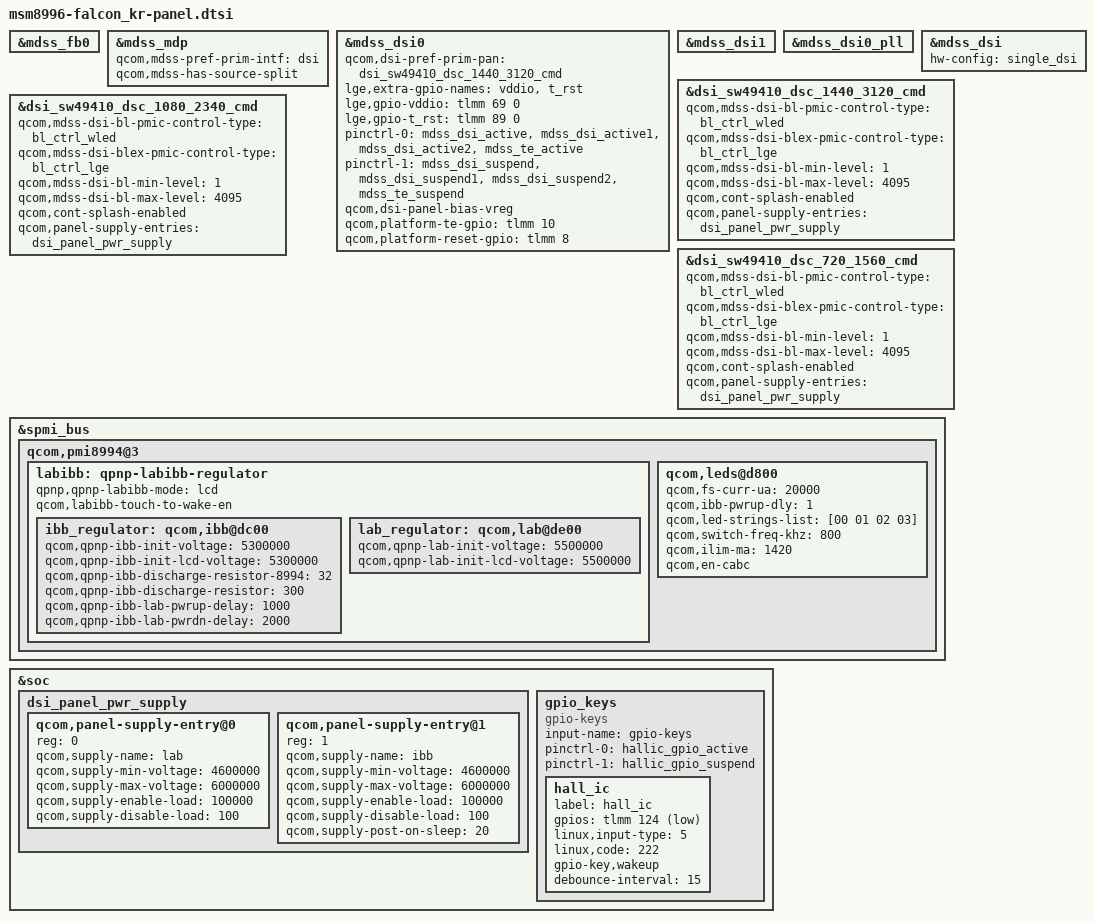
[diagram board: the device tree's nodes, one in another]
/* Copyright (c) 2015, The Linux Foundation. All rights reserved.
 *
 * This program is free software; you can redistribute it and/or modify
 * it under the terms of the GNU General Public License version 2 and
 * only version 2 as published by the Free Software Foundation.
 *
 * This program is distributed in the hope that it will be useful,
 * but WITHOUT ANY WARRANTY; without even the implied warranty of
 * MERCHANTABILITY or FITNESS FOR A PARTICULAR PURPOSE.  See the
 * GNU General Public License for more details.
 */

#include "../dsi-panel-sw49410-dsc-1440-3120-cmd.dtsi"
#include "../dsi-panel-sw49410-dsc-1080-2340-cmd.dtsi"
#include "../dsi-panel-sw49410-dsc-720-1560-cmd.dtsi"

&mdss_fb0 {
	/delete-node/ qcom,cont-splash-memory;
};

&mdss_mdp {
	qcom,mdss-pref-prim-intf = "dsi";
	qcom,mdss-has-source-split;
};

&mdss_dsi0 {
	qcom,dsi-pref-prim-pan = <&dsi_sw49410_dsc_1440_3120_cmd>;
	lge,extra-gpio-names = "vddio", "t_rst";
	lge,gpio-vddio = <&tlmm 69 0>;
	lge,gpio-t_rst = <&tlmm 89 0>;
	pinctrl-names = "mdss_default", "mdss_sleep";
	pinctrl-0 = <&mdss_dsi_active &mdss_dsi_active1 &mdss_dsi_active2  &mdss_te_active>;
	pinctrl-1 = <&mdss_dsi_suspend &mdss_dsi_suspend1 &mdss_dsi_suspend2 &mdss_te_suspend>;
	qcom,dsi-panel-bias-vreg;
	qcom,platform-te-gpio = <&tlmm 10 0>;
	qcom,platform-reset-gpio = <&tlmm 8 0>;

	/delete-property/vddio-supply;
	/delete-property/qcom,null-insertion-enabled;
};

&mdss_dsi1 {
	/delete-property/cell-index;
};

&mdss_dsi0_pll {
		/delete-property/ memory-region;
};

&mdss_dsi {
	hw-config = "single_dsi";
};

&labibb {
	status = "ok";
	qpnp,qpnp-labibb-mode = "lcd";
	qcom,labibb-touch-to-wake-en;
};

&ibb_regulator {
	qcom,qpnp-ibb-discharge-resistor-8994 = <32>;
	qcom,qpnp-ibb-discharge-resistor = <300>;
	qcom,qpnp-ibb-lab-pwrup-delay = <1000>;
	qcom,qpnp-ibb-lab-pwrdn-delay = <2000>;
};

&dsi_sw49410_dsc_1440_3120_cmd {
	qcom,mdss-dsi-bl-pmic-control-type = "bl_ctrl_wled";
	qcom,mdss-dsi-blex-pmic-control-type = "bl_ctrl_lge";
	qcom,mdss-dsi-bl-min-level = <1>;
	qcom,mdss-dsi-bl-max-level = <4095>;
	qcom,cont-splash-enabled;
	qcom,panel-supply-entries = <&dsi_panel_pwr_supply>;
};

&dsi_sw49410_dsc_1080_2340_cmd {
	qcom,mdss-dsi-bl-pmic-control-type = "bl_ctrl_wled";
	qcom,mdss-dsi-blex-pmic-control-type = "bl_ctrl_lge";
	qcom,mdss-dsi-bl-min-level = <1>;
	qcom,mdss-dsi-bl-max-level = <4095>;
	qcom,cont-splash-enabled;
	qcom,panel-supply-entries = <&dsi_panel_pwr_supply>;
};

&dsi_sw49410_dsc_720_1560_cmd {
	qcom,mdss-dsi-bl-pmic-control-type = "bl_ctrl_wled";
	qcom,mdss-dsi-blex-pmic-control-type = "bl_ctrl_lge";
	qcom,mdss-dsi-bl-min-level = <1>;
	qcom,mdss-dsi-bl-max-level = <4095>;
	qcom,cont-splash-enabled;
	qcom,panel-supply-entries = <&dsi_panel_pwr_supply>;
};

&spmi_bus {
	qcom,pmi8994@3 {
		labibb: qpnp-labibb-regulator {
			ibb_regulator: qcom,ibb@dc00 {
				qcom,qpnp-ibb-init-voltage = <5300000>;
				qcom,qpnp-ibb-init-lcd-voltage = <5300000>;
			};
			lab_regulator: qcom,lab@de00 {
				qcom,qpnp-lab-init-voltage = <5500000>;
				qcom,qpnp-lab-init-lcd-voltage = <5500000>;
			};
		};

		qcom,leds@d800 {
			qcom,fs-curr-ua = <20000>;
			qcom,ibb-pwrup-dly = <1>;
			qcom,led-strings-list = [00 01 02 03];
			qcom,switch-freq-khz = <800>;
			qcom,ilim-ma = <1420>;
			qcom,en-cabc;
		};
	};
};

&soc {
	dsi_panel_pwr_supply: dsi_panel_pwr_supply {
		#address-cells = <1>;
		#size-cells = <0>;

		qcom,panel-supply-entry@0 {
			reg = <0>;
			qcom,supply-name = "lab";
			qcom,supply-min-voltage = <4600000>;
			qcom,supply-max-voltage = <6000000>;
			qcom,supply-enable-load = <100000>;
			qcom,supply-disable-load = <100>;
		};

		qcom,panel-supply-entry@1 {
			reg = <1>;
			qcom,supply-name = "ibb";
			qcom,supply-min-voltage = <4600000>;
			qcom,supply-max-voltage = <6000000>;
			qcom,supply-enable-load = <100000>;
			qcom,supply-disable-load = <100>;
			qcom,supply-post-on-sleep = <20>;
		};
	};

	gpio_keys {
		compatible = "gpio-keys";
		input-name = "gpio-keys";

		pinctrl-names = "tlmm_gpio_key_active","tlmm_gpio_key_suspend";
		pinctrl-0 = <&hallic_gpio_active>;
		pinctrl-1 = <&hallic_gpio_suspend>;

		hall_ic {
			label = "hall_ic";
			gpios = <&tlmm 124 0x1>;
			linux,input-type = <5>;
			linux,code = <222>;
			gpio-key,wakeup;
			debounce-interval = <15>;
		};
	};
};
